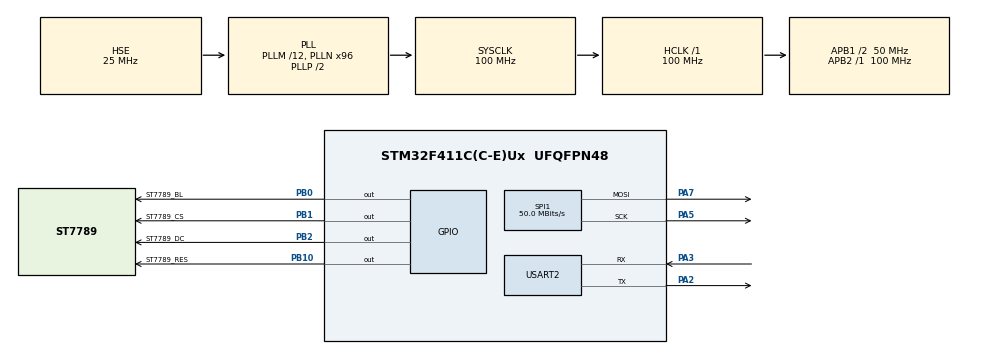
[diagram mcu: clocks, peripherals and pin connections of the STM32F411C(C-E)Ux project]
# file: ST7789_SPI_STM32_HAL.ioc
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Mcu.Family=STM32F4
RCC.PLLSourceVirtual=RCC_PLLSOURCE_HSE
PB10.PinState=GPIO_PIN_SET
RCC.CortexFreq_Value=100000000
PA7.Mode=TX_Only_Simplex_Unidirect_Master
SPI1.VirtualType=VM_MASTER
PB10.GPIO_PuPd=GPIO_PULLUP
PH1\ -\ OSC_OUT.Mode=HSE-External-Oscillator
PB0.GPIO_Label=ST7789_BL
RCC.APB1CLKDivider=RCC_HCLK_DIV2
NVIC.USART2_IRQn=true\:0\:0\:false\:false\:true\:true\:true
RCC.SYSCLKSource=RCC_SYSCLKSOURCE_PLLCLK
ProjectManager.StackSize=0x400
PA13.Signal=SYS_JTMS-SWDIO
PA3.Mode=Asynchronous
PH0\ -\ OSC_IN.Mode=HSE-External-Oscillator
PH0\ -\ OSC_IN.Signal=RCC_OSC_IN
ProjectManager.TargetToolchain=STM32CubeIDE
PB10.GPIO_Label=ST7789_RES
SPI1.Direction=SPI_DIRECTION_2LINES
PB1.GPIO_PuPd=GPIO_PULLUP
RCC.HCLKFreq_Value=100000000
RCC.APB2TimFreq_Value=100000000
SPI1.CalculateBaudRate=50.0 MBits/s
RCC.LSE_VALUE=32768
RCC.AHBFreq_Value=100000000
PB10.Signal=GPIO_Output
PA5.Signal=SPI1_SCK
RCC.HSE_VALUE=25000000
PH1\ -\ OSC_OUT.Signal=RCC_OSC_OUT
PB2.Signal=GPIO_Output
board=custom
RCC.VCOOutputFreq_Value=200000000
RCC.APB2Freq_Value=100000000
SPI1.Mode=SPI_MODE_MASTER
PA14.Mode=Serial_Wire
PB1.GPIO_Label=ST7789_CS
PA13.Mode=Serial_Wire
Mcu.Name=STM32F411C(C-E)Ux
PA2.Signal=USART2_TX
PB1.PinState=GPIO_PIN_SET
RCC.48MHZClocksFreq_Value=50000000
RCC.SYSCLKFreq_VALUE=100000000
Mcu.Package=UFQFPN48
PB1.Signal=GPIO_Output
USART2.VirtualMode=VM_ASYNC
PA14.Signal=SYS_JTCK-SWCLK
PB2.GPIO_Label=ST7789_DC
ProjectManager.HeapSize=0x200
RCC.HSI_VALUE=16000000
NVIC.PriorityGroup=NVIC_PRIORITYGROUP_4
RCC.PLLM=12
RCC.PLLN=96
RCC.APB1TimFreq_Value=100000000
PA2.Mode=Asynchronous
RCC.APB1Freq_Value=50000000
PB0.Signal=GPIO_Output
PA3.Signal=USART2_RX
PA5.Mode=TX_Only_Simplex_Unidirect_Master
PA7.Signal=SPI1_MOSI

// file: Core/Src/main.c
/* USER CODE BEGIN Header */
/**
  ******************************************************************************
  * @file           : main.c
  * @brief          : Main program body
  ******************************************************************************
  * @attention
  *
  * <h2><center>&copy; Copyright (c) 2021 STMicroelectronics.
  * All rights reserved.</center></h2>
  *
  * This software component is licensed by ST under BSD 3-Clause license,
  * the "License"; You may not use this file except in compliance with the
  * License. You may obtain a copy of the License at:
  *                        opensource.org/licenses/BSD-3-Clause
  *
  ******************************************************************************
  */
/* USER CODE END Header */
#include "main.h"

/* USER CODE BEGIN Includes */
#include "defines.h"
#include <stdio.h>
/* USER CODE END Includes */

SPI_HandleTypeDef hspi1;

UART_HandleTypeDef huart2;

void SystemClock_Config(void);
static void MX_GPIO_Init(void);
static void MX_SPI1_Init(void);
static void MX_USART2_UART_Init(void);

int main(void)
{

  /* MCU Configuration--------------------------------------------------------*/

  /* Reset of all peripherals, Initializes the Flash interface and the Systick. */
  HAL_Init();

  /* Configure the system clock */
  SystemClock_Config();

  /* Initialize all configured peripherals */
  MX_GPIO_Init();
  MX_SPI1_Init();
  MX_USART2_UART_Init();
  /* USER CODE BEGIN 2 */
  printf("[%8lu] Debug UART2 is OK!\r\n", HAL_GetTick());
  /* USER CODE END 2 */

  /* Infinite loop */
  /* USER CODE BEGIN WHILE */
  while (1)
  {
	  printf("[%8lu] Current tick\r\n", HAL_GetTick());
	  HAL_Delay(1000);
    /* USER CODE END WHILE */

  }
}

void SystemClock_Config(void)
{
  RCC_OscInitTypeDef RCC_OscInitStruct = {0};
  RCC_ClkInitTypeDef RCC_ClkInitStruct = {0};

  /** Configure the main internal regulator output voltage
  */
  __HAL_RCC_PWR_CLK_ENABLE();
  __HAL_PWR_VOLTAGESCALING_CONFIG(PWR_REGULATOR_VOLTAGE_SCALE1);
  /** Initializes the RCC Oscillators according to the specified parameters
  * in the RCC_OscInitTypeDef structure.
  */
  RCC_OscInitStruct.OscillatorType = RCC_OSCILLATORTYPE_HSE;
  RCC_OscInitStruct.HSEState = RCC_HSE_ON;
  RCC_OscInitStruct.PLL.PLLState = RCC_PLL_ON;
  RCC_OscInitStruct.PLL.PLLSource = RCC_PLLSOURCE_HSE;
  RCC_OscInitStruct.PLL.PLLM = 12;
  RCC_OscInitStruct.PLL.PLLN = 96;
  RCC_OscInitStruct.PLL.PLLP = RCC_PLLP_DIV2;
  RCC_OscInitStruct.PLL.PLLQ = 4;
  if (HAL_RCC_OscConfig(&RCC_OscInitStruct) != HAL_OK)
  {
    Error_Handler();
  }
  /** Initializes the CPU, AHB and APB buses clocks
  */
  RCC_ClkInitStruct.ClockType = RCC_CLOCKTYPE_HCLK|RCC_CLOCKTYPE_SYSCLK
                              |RCC_CLOCKTYPE_PCLK1|RCC_CLOCKTYPE_PCLK2;
  RCC_ClkInitStruct.SYSCLKSource = RCC_SYSCLKSOURCE_PLLCLK;
  RCC_ClkInitStruct.AHBCLKDivider = RCC_SYSCLK_DIV1;
  RCC_ClkInitStruct.APB1CLKDivider = RCC_HCLK_DIV2;
  RCC_ClkInitStruct.APB2CLKDivider = RCC_HCLK_DIV1;

  if (HAL_RCC_ClockConfig(&RCC_ClkInitStruct, FLASH_LATENCY_3) != HAL_OK)
  {
    Error_Handler();
  }
}

static void MX_SPI1_Init(void)
{

  /* SPI1 parameter configuration*/
  hspi1.Instance = SPI1;
  hspi1.Init.Mode = SPI_MODE_MASTER;
  hspi1.Init.Direction = SPI_DIRECTION_2LINES;
  hspi1.Init.DataSize = SPI_DATASIZE_8BIT;
  hspi1.Init.CLKPolarity = SPI_POLARITY_LOW;
  hspi1.Init.CLKPhase = SPI_PHASE_1EDGE;
  hspi1.Init.NSS = SPI_NSS_SOFT;
  hspi1.Init.BaudRatePrescaler = SPI_BAUDRATEPRESCALER_2;
  hspi1.Init.FirstBit = SPI_FIRSTBIT_MSB;
  hspi1.Init.TIMode = SPI_TIMODE_DISABLE;
  hspi1.Init.CRCCalculation = SPI_CRCCALCULATION_DISABLE;
  hspi1.Init.CRCPolynomial = 10;
  if (HAL_SPI_Init(&hspi1) != HAL_OK)
  {
    Error_Handler();
  }

}

static void MX_USART2_UART_Init(void)
{

  huart2.Instance = USART2;
  huart2.Init.BaudRate = 115200;
  huart2.Init.WordLength = UART_WORDLENGTH_8B;
  huart2.Init.StopBits = UART_STOPBITS_1;
  huart2.Init.Parity = UART_PARITY_NONE;
  huart2.Init.Mode = UART_MODE_TX_RX;
  huart2.Init.HwFlowCtl = UART_HWCONTROL_NONE;
  huart2.Init.OverSampling = UART_OVERSAMPLING_16;
  if (HAL_UART_Init(&huart2) != HAL_OK)
  {
    Error_Handler();
  }

}

static void MX_GPIO_Init(void)
{
  GPIO_InitTypeDef GPIO_InitStruct = {0};

  /* GPIO Ports Clock Enable */
  __HAL_RCC_GPIOH_CLK_ENABLE();
  __HAL_RCC_GPIOA_CLK_ENABLE();
  __HAL_RCC_GPIOB_CLK_ENABLE();

  /*Configure GPIO pin Output Level */
  HAL_GPIO_WritePin(GPIOB, ST7789_BL_Pin|ST7789_DC_Pin, GPIO_PIN_RESET);

  /*Configure GPIO pin Output Level */
  HAL_GPIO_WritePin(GPIOB, ST7789_CS_Pin|ST7789_RES_Pin, GPIO_PIN_SET);

  /*Configure GPIO pins : ST7789_BL_Pin ST7789_DC_Pin */
  GPIO_InitStruct.Pin = ST7789_BL_Pin|ST7789_DC_Pin;
  GPIO_InitStruct.Mode = GPIO_MODE_OUTPUT_PP;
  GPIO_InitStruct.Pull = GPIO_NOPULL;
  GPIO_InitStruct.Speed = GPIO_SPEED_FREQ_LOW;
  HAL_GPIO_Init(GPIOB, &GPIO_InitStruct);

  /*Configure GPIO pins : ST7789_CS_Pin ST7789_RES_Pin */
  GPIO_InitStruct.Pin = ST7789_CS_Pin|ST7789_RES_Pin;
  GPIO_InitStruct.Mode = GPIO_MODE_OUTPUT_PP;
  GPIO_InitStruct.Pull = GPIO_PULLUP;
  GPIO_InitStruct.Speed = GPIO_SPEED_FREQ_LOW;
  HAL_GPIO_Init(GPIOB, &GPIO_InitStruct);

}

void Error_Handler(void)
{
  __disable_irq();
  while (1)
  {
  }
}

/************************ (C) COPYRIGHT STMicroelectronics *****END OF FILE****/
